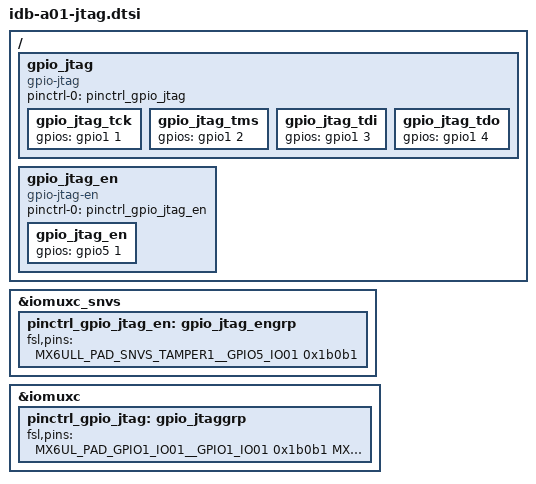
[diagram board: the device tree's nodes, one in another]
/*
 * Copyright (C) 2019 Variscite Ltd. - https://www.variscite.com
 *
 * This program is free software; you can redistribute it and/or modify
 * it under the terms of the GNU General Public License version 2 as
 * published by the Free Software Foundation.
 */

/ {
	gpio_jtag {
		compatible = "gpio-jtag";
		pinctrl-names = "default";
		pinctrl-0 = <&pinctrl_gpio_jtag>;
		status = "okay";

		gpio_jtag_tck {
			gpios = <&gpio1 1 GPIO_ACTIVE_HIGH>;
		};
		gpio_jtag_tms {
			gpios = <&gpio1 2 GPIO_ACTIVE_HIGH>;
		};
		gpio_jtag_tdi {
			gpios = <&gpio1 3 GPIO_ACTIVE_HIGH>;
		};
		gpio_jtag_tdo {
			gpios = <&gpio1 4 GPIO_ACTIVE_HIGH>;
		};
	};	
	
	gpio_jtag_en {
		compatible = "gpio-jtag-en";
		pinctrl-names = "default";
		pinctrl-0 = <&pinctrl_gpio_jtag_en>;
		status = "okay";
		
		gpio_jtag_en {
			gpios = <&gpio5 1 GPIO_ACTIVE_HIGH>;
		};
	};
		
};

&iomuxc_snvs {
	pinctrl_gpio_jtag_en: gpio_jtag_engrp {
		fsl,pins = <
			MX6ULL_PAD_SNVS_TAMPER1__GPIO5_IO01	0x1b0b1
		>;
	};		
};

&iomuxc {
	pinctrl_gpio_jtag: gpio_jtaggrp {
		fsl,pins = <
			MX6UL_PAD_GPIO1_IO01__GPIO1_IO01	0x1b0b1
			MX6UL_PAD_GPIO1_IO02__GPIO1_IO02	0x1b0b1
			MX6UL_PAD_GPIO1_IO03__GPIO1_IO03	0x1b0b1
			MX6UL_PAD_GPIO1_IO04__GPIO1_IO04	0x1b0b1
		>;
	};
};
